# Baikal-U register map
Vendor: BAIKAL ELECTRONICS, JSC; File version: 1.0
CPU: RISC-V r0p0, little endian, no MPU, no FPU, 3 interrupt priority bits
Registers are 32-bit, read-write, reset 0x0 unless marked. A register's access mark holds for its fields unless they carry their own. Offsets are from the block's base; [hi:lo] are bit positions; {n}, {i} and the like mark numbered series; 'fields as' and 'values as' point back to an identical list.

## DMA — Direct Memory Access Controller
Base 0x15100000
Same registers: DMA1 0x15101000, DMA2 0x15102000
{0x0+0x58*i} CH_SAR{i} (i=0..7) — Source Address Register for Channel {i}
  [31:0] CH_SAR — Source address of DMA transfer
{0x8+0x58*i} CH_DAR{i} (i=0..7) — Destination Address Register for Channel {i}
  [31:0] CH_DAR — Destination address of DMA transfer
{0x10+0x58*i} CH_LLP{i} (i=0..7) — Linked List Pointer Register for Channel {i}
  [31:2] LOC — Start address of the next LLI
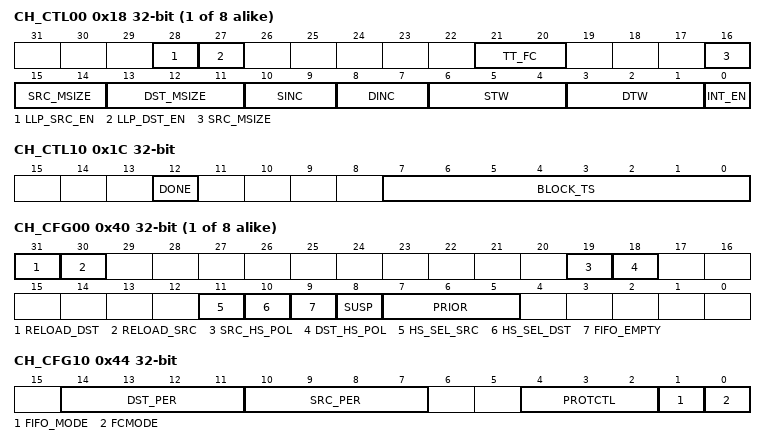
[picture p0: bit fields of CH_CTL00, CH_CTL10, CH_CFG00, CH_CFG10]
{0x18+0x58*i} CH_CTL{i:02} (i=0..7) — Control Register 0 for Channel {i}
  [28] LLP_SRC_EN — Enable block chaining using Linked List on the source side
    0=DISABLE; 1=ENABLE
  [27] LLP_DST_EN — Enable block chaining using Linked List on the destination side
    0=DISABLE; 1=ENABLE
  [21:20] TT_FC — Transfer type and flow control
    0=Transfer type is Memory to Memory and Flow Controller is DMA Controller; 1=Transfer type is Memory to Peripheral and Flow Controller is DMA Controller; 2=Transfer type is Peripheral to Memory and Flow Controller is DMA Controller; 3=Transfer type is Peripheral to Peripheral and Flow Controller is DMA Controller
  [16:14] SRC_MSIZE — Source burst transaction length
    0=Number of data items to be transferred is 1; 1=Number of data items to be transferred is 4; 2=Number of data items to be transferred is 8; 3=Number of data items to be transferred is 16; 4=Number of data items to be transferred is 32; 5=Number of data items to be transferred is 64; 6=Number of data items to be transferred is 128; 7=Number of data items to be transferred is 256
  [13:11] DST_MSIZE — Destination burst transaction length
    values as SRC_MSIZE
  [10:9] SINC — Source address increment
    0=Increments the source address; 1=Decrements the source address; 2=No change in the source address; 3=No change in the source address
  [8:7] DINC — Destination address increment
    0=Increments the destination address; 1=Decrements the destination address; 2=No change in the destination address; 3=No change in the destination address
  [6:4] STW — Source transfer width
    0=Source transfer width is 8 bits; 1=Source transfer width is 16 bits; 2=Source transfer width is 32 bits
  [3:1] DTW — Destination transfer width
    0=Destination transfer width is 8 bits; 1=Destination transfer width is 16 bits; 2=Destination transfer width is 32 bits
  [0] INT_EN — Interrupt enable
    0=DISABLE (Interrupts disabled); 1=ENABLE (Interrupts enabled)
0x1C CH_CTL10 — Control Register 1 for Channel 0
  [12] DONE — Block transfer is done
    0=DISABLE; 1=ENABLE
  [7:0] BLOCK_TS — Block transfer size
{0x40+0x58*i} CH_CFG{i:02} (i=0..7) — Configuration Register 0 for Channel {i}
  [31] RELOAD_DST — Automatic destination reload
    0=DISABLE; 1=ENABLE
  [30] RELOAD_SRC — Automatic source reload
    0=DISABLE; 1=ENABLE
  [19] SRC_HS_POL — Source handshaking interface polarity
    0=ACTIVE_HIGH; 1=ACTIVE_LOW
  [18] DST_HS_POL — Destination handshaking interface polarity
    0=ACTIVE_HIGH; 1=ACTIVE_LOW
  [11] HS_SEL_SRC — Source handshaking select
    0=HW (Hardware handshaking interface); 1=SW (Software handshaking interface)
  [10] HS_SEL_DST — Destination handshaking select
    values as HS_SEL_SRC
  [9] FIFO_EMPTY — Channel FIFO status
    0=DISABLE; 1=ENABLE
  [8] SUSP — Channel suspend
    0=DISABLE; 1=ENABLE
  [7:5] PRIOR — Channel priority
    {v}=Channel priority is {v} (v=0..7)
0x44 CH_CFG10 — Configuration Register 1 for Channel 0
  [14:11] DST_PER — Destination hardware interface
  [10:7] SRC_PER — Source hardware interface
  [4:2] PROTCTL — Protection control
    {v}=Drive the AHB HPROT[{v}] bus (v=0..7)
  [1] FIFO_MODE — FIFO mode select
    0=FIFO can transmit or accept a single AHB transfer; 1=FIFO is less or equal than half full to fetch data from source or greater or equal than half full to send data to destination
  [0] FCMODE — Flow control mode
    0=Source transaction requests are serviced when they occur; 1=Source transaction requests are not serviced until a destination transaction request occurs
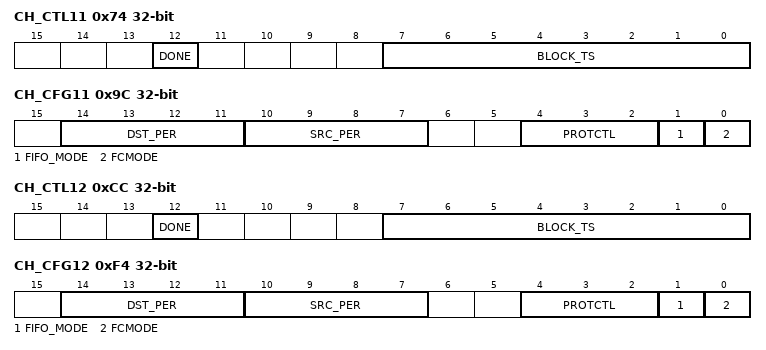
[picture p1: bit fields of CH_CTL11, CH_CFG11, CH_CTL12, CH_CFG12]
0x74 CH_CTL11 — Control Register 1 for Channel 1
  fields as CH_CTL10
0x9C CH_CFG11 — Configuration Register 1 for Channel 1
  fields as CH_CFG10
0xCC CH_CTL12 — Control Register 1 for Channel 2
  fields as CH_CTL10
0xF4 CH_CFG12 — Configuration Register 1 for Channel 2
  fields as CH_CFG10
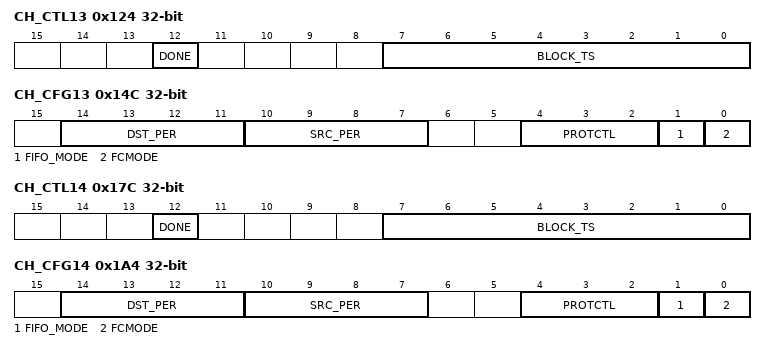
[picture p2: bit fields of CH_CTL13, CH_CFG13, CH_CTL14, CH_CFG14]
0x124 CH_CTL13 — Control Register 1 for Channel 3
  fields as CH_CTL10
0x14C CH_CFG13 — Configuration Register 1 for Channel 3
  fields as CH_CFG10
0x17C CH_CTL14 — Control Register 1 for Channel 4
  fields as CH_CTL10
0x1A4 CH_CFG14 — Configuration Register 1 for Channel 4
  fields as CH_CFG10
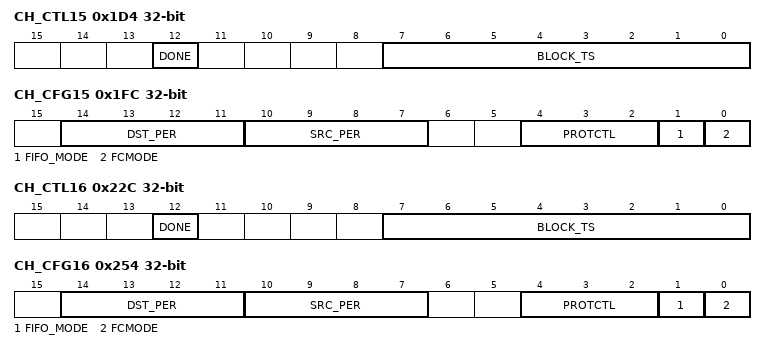
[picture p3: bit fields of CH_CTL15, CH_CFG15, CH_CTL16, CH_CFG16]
0x1D4 CH_CTL15 — Control Register 1 for Channel 5
  fields as CH_CTL10
0x1FC CH_CFG15 — Configuration Register 1 for Channel 5
  fields as CH_CFG10
0x22C CH_CTL16 — Control Register 1 for Channel 6
  fields as CH_CTL10
0x254 CH_CFG16 — Configuration Register 1 for Channel 6
  fields as CH_CFG10
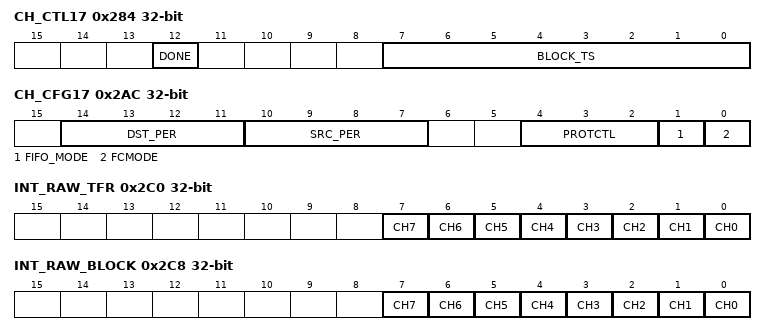
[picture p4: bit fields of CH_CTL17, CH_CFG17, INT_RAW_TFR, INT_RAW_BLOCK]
0x284 CH_CTL17 — Control Register 1 for Channel 7
  fields as CH_CTL10
0x2AC CH_CFG17 — Configuration Register 1 for Channel 7
  fields as CH_CFG10
0x2C0 INT_RAW_TFR — Raw Status for IntTfr Interrupt
  [all] fields
    0=DISABLE; 1=ENABLE
  [n] CH{n} (n=0..7) — Channel {n} raw status for IntTfr interrupt
0x2C8 INT_RAW_BLOCK — Raw Status for IntBlock Interrupt
  [all] fields
    0=DISABLE; 1=ENABLE
  [n] CH{n} (n=0..7) — Channel {n} raw status for IntBlock interrupt
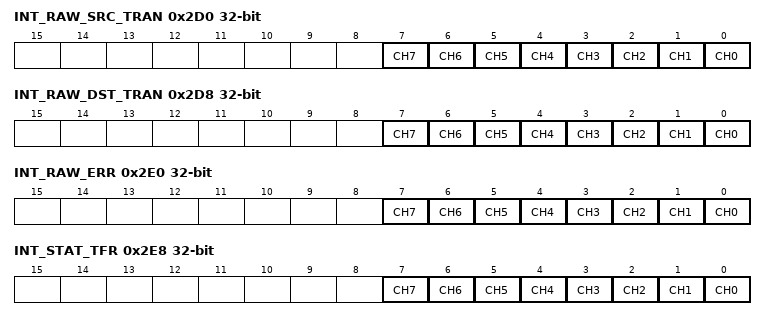
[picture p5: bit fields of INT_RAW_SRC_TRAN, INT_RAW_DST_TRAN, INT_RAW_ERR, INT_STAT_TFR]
0x2D0 INT_RAW_SRC_TRAN — Raw Status for IntSrcTran Interrupt
  [all] fields
    0=DISABLE; 1=ENABLE
  [n] CH{n} (n=0..7) — Channel {n} raw status for IntSrcTran interrupt
0x2D8 INT_RAW_DST_TRAN — Raw Status for IntDstTran Interrupt
  [all] fields
    0=DISABLE; 1=ENABLE
  [n] CH{n} (n=0..7) — Channel {n} raw status for IntDstTran interrupt
0x2E0 INT_RAW_ERR — Raw Status for IntErr Interrupt
  [all] fields
    0=DISABLE; 1=ENABLE
  [n] CH{n} (n=0..7) — Channel {n} raw status for IntErr interrupt
0x2E8 INT_STAT_TFR — Status for IntTfr Interrupt
  [all] fields
    0=DISABLE; 1=ENABLE
  [n] CH{n} (n=0..7) — Channel {n} status for IntTfr interrupt
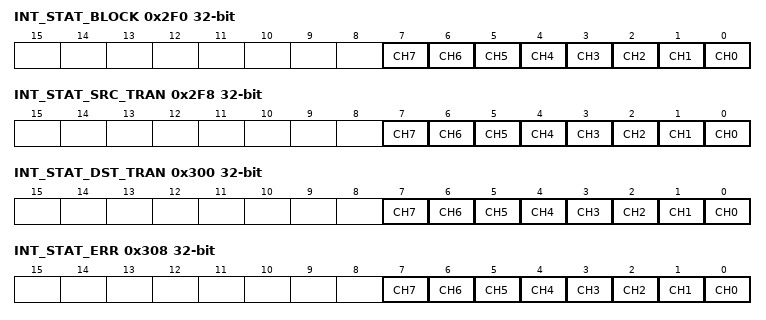
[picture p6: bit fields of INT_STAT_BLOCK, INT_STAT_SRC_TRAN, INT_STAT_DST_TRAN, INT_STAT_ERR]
0x2F0 INT_STAT_BLOCK — Status for IntBlock Interrupt
  [all] fields
    0=DISABLE; 1=ENABLE
  [n] CH{n} (n=0..7) — Channel {n} status for IntBlock interrupt
0x2F8 INT_STAT_SRC_TRAN — Status for IntSrcTran Interrupt
  [all] fields
    0=DISABLE; 1=ENABLE
  [n] CH{n} (n=0..7) — Channel {n} status for IntSrcTran interrupt
0x300 INT_STAT_DST_TRAN — Status for IntDstTran Interrupt
  [all] fields
    0=DISABLE; 1=ENABLE
  [n] CH{n} (n=0..7) — Channel {n} status for IntDstTran interrupt
0x308 INT_STAT_ERR — Status for IntErr Interrupt
  [all] fields
    0=DISABLE; 1=ENABLE
  [n] CH{n} (n=0..7) — Channel {n} status for IntErr interrupt
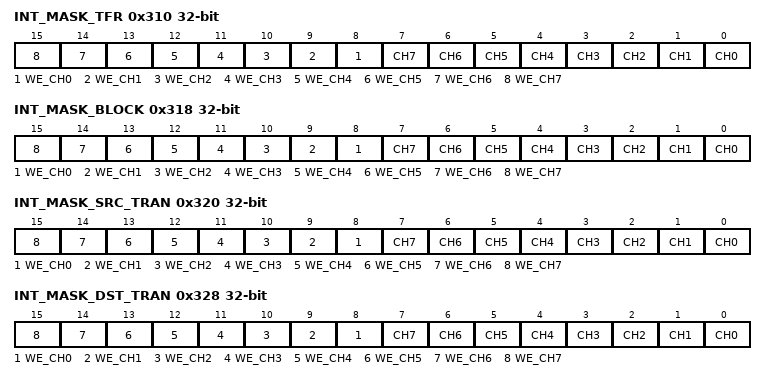
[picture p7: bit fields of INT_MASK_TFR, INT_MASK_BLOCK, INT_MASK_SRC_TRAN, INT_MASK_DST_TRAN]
0x310 INT_MASK_TFR — Mask for IntTfr Interrupt
  [all] fields
    0=DISABLE; 1=ENABLE
  [n+8] WE_CH{n} (n=0..7) — Channel {n} mask write enable for IntTfr interrupt
  [n] CH{n} (n=0..7) — Channel {n} mask for IntTfr interrupt
0x318 INT_MASK_BLOCK — Mask for IntBlock Interrupt
  [all] fields
    0=DISABLE; 1=ENABLE
  [n+8] WE_CH{n} (n=0..7) — Channel {n} mask write enable for IntBlock interrupt
  [n] CH{n} (n=0..7) — Channel {n} mask for IntBlock interrupt
0x320 INT_MASK_SRC_TRAN — Mask for IntSrcTran Interrupt
  [all] fields
    0=DISABLE; 1=ENABLE
  [n+8] WE_CH{n} (n=0..7) — Channel {n} mask write enable for IntSrcTran interrupt
  [n] CH{n} (n=0..7) — Channel {n} mask for IntSrcTran interrupt
0x328 INT_MASK_DST_TRAN — Mask for IntDstTran Interrupt
  [all] fields
    0=DISABLE; 1=ENABLE
  [n+8] WE_CH{n} (n=0..7) — Channel {n} mask write enable for IntDstTran interrupt
  [n] CH{n} (n=0..7) — Channel {n} mask for IntDstTran interrupt
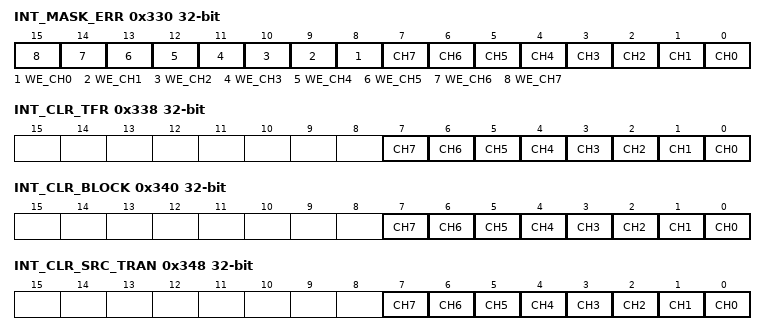
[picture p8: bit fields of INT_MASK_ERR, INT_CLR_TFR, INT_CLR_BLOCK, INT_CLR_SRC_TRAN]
0x330 INT_MASK_ERR — Mask for IntErr Interrupt
  [all] fields
    0=DISABLE; 1=ENABLE
  [n+8] WE_CH{n} (n=0..7) — Channel {n} mask write enable for IntErr interrupt
  [n] CH{n} (n=0..7) — Channel {n} mask for IntErr interrupt
0x338 INT_CLR_TFR — Clear for IntTfr Interrupt
  [all] fields
    0=DISABLE; 1=ENABLE
  [n] CH{n} (n=0..7) — Channel {n} clear for IntTfr interrupt
0x340 INT_CLR_BLOCK — Clear for IntBlock Interrupt
  [all] fields
    0=DISABLE; 1=ENABLE
  [n] CH{n} (n=0..7) — Channel {n} clear for IntBlock interrupt
0x348 INT_CLR_SRC_TRAN — Clear for IntSrcTran Interrupt
  [all] fields
    0=DISABLE; 1=ENABLE
  [n] CH{n} (n=0..7) — Channel {n} clear for IntSrcTran interrupt
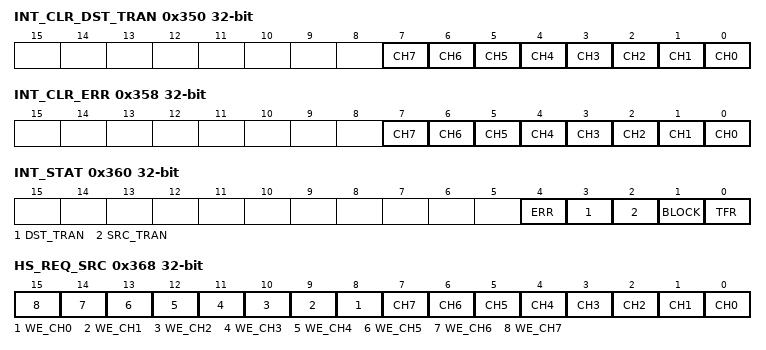
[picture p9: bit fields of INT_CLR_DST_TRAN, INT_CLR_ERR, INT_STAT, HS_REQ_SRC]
0x350 INT_CLR_DST_TRAN — Clear for IntDstTran Interrupt
  [all] fields
    0=DISABLE; 1=ENABLE
  [n] CH{n} (n=0..7) — Channel {n} clear for IntDstTran interrupt
0x358 INT_CLR_ERR — Clear for IntErr Interrupt
  [all] fields
    0=DISABLE; 1=ENABLE
  [n] CH{n} (n=0..7) — Channel {n} clear for IntErr interrupt
0x360 INT_STAT — Status for each Interrupt type
  [all] fields
    0=DISABLE; 1=ENABLE
  [4] ERR — OR of the contents of STAT_ERR register
  [3] DST_TRAN — OR of the contents of STAT_DST_TRAN register
  [2] SRC_TRAN — OR of the contents of STAT_SRC_TRAN register
  [1] BLOCK — OR of the contents of STAT_BLOCK register
  [0] TFR — OR of the contents of STAT_TFR register
0x368 HS_REQ_SRC — Source Software Transaction Request Register
  [all] fields
    0=DISABLE; 1=ENABLE
  [n+8] WE_CH{n} (n=0..7) — Channel {n} source software transaction request write enable
  [n] CH{n} (n=0..7) — Channel {n} source software transaction request
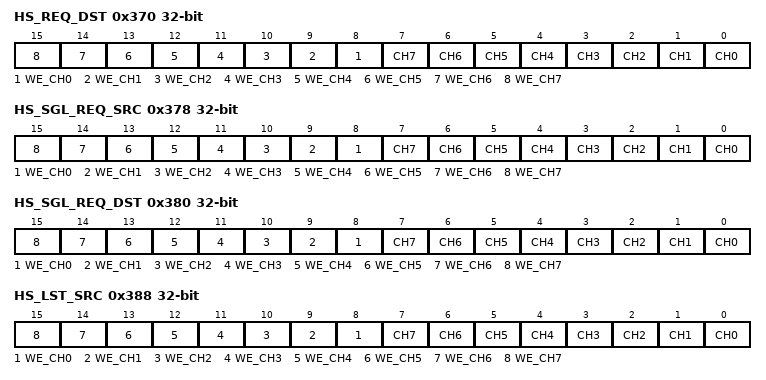
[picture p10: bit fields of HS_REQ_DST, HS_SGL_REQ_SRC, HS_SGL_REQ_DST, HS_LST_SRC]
0x370 HS_REQ_DST — Destination Software Transaction Request Register
  [all] fields
    0=DISABLE; 1=ENABLE
  [n+8] WE_CH{n} (n=0..7) — Channel {n} destination software transaction request write enable
  [n] CH{n} (n=0..7) — Channel {n} destination software transaction request
0x378 HS_SGL_REQ_SRC — Source Single Transaction Request Register
  [all] fields
    0=DISABLE; 1=ENABLE
  [n+8] WE_CH{n} (n=0..7) — Channel {n} source single transaction request write enable
  [n] CH{n} (n=0..7) — Channel {n} source single transaction request
0x380 HS_SGL_REQ_DST — Destination Single Transaction Request Register
  [all] fields
    0=DISABLE; 1=ENABLE
  [n+8] WE_CH{n} (n=0..7) — Channel {n} destination single transaction request write enable
  [n] CH{n} (n=0..7) — Channel {n} destination single transaction request
0x388 HS_LST_SRC — Source Last Transaction Request Register
  [all] fields
    0=DISABLE; 1=ENABLE
  [n+8] WE_CH{n} (n=0..7) — Channel {n} source last transaction request write enable
  [n] CH{n} (n=0..7) — Channel {n} source last transaction request
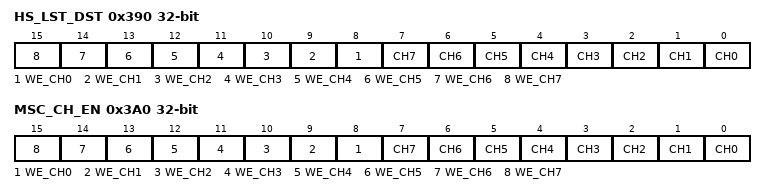
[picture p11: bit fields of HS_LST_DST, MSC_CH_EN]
0x390 HS_LST_DST — Destination Last Transaction Request Register
  [all] fields
    0=DISABLE; 1=ENABLE
  [n+8] WE_CH{n} (n=0..7) — Channel {n} destination last transaction request write enable
  [n] CH{n} (n=0..7) — Channel {n} destination last transaction request
0x398 MSC_CFG — Configuration Register
  [0] EN — DMA controller enable
    0=DISABLE; 1=ENABLE
0x3A0 MSC_CH_EN — Channel Enable Register
  [all] fields
    0=DISABLE; 1=ENABLE
  [n+8] WE_CH{n} (n=0..7) — Channel {n} enable write enable
  [n] CH{n} (n=0..7) — Channel {n} enable
0x3A8 MSC_ID — ID Register
  [31:0] MSC_ID — DMA controller peripheral ID
0x3B0 MSC_TEST — Test Register
  [0] SLV_IF — DMA test mode
    0=DISABLE; 1=ENABLE
0x3F8 MSC_COMP_TYPE — Component Type Register
  [31:0] MSC_COMP_TYPE — DMA component type
0x3FC MSC_COMP_VERSION — Component Version Register
  [31:0] MSC_COMP_VERSION — DMA component version
